# S6E1C3xD register map
Vendor: Cypress; File version: 2.1
CPU: CM0PLUS r0p1, little endian, no MPU, no FPU, 2 interrupt priority bits
Registers are 32-bit, read-write, reset 0x0 unless marked. A register's access mark holds for its fields unless they carry their own. Offsets are from the block's base; [hi:lo] are bit positions; {n}, {i} and the like mark numbered series.

## FASTIO — Fast GPIO Registers
Base 0xF8000000
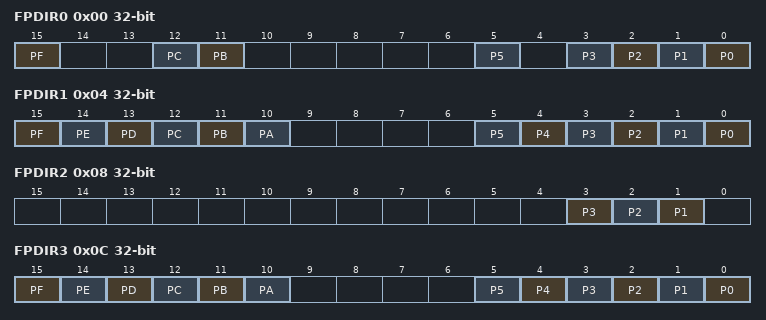
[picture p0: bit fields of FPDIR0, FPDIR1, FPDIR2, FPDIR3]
0x00 FPDIR0 ro — Fast GPIO Input Data Register 0 [BHW]
  [15] PF rw — Bit15 of FPDIR0
  [12] PC rw — Bit12 of FPDIR0
  [11] PB rw — Bit11 of FPDIR0
  [5] P5 rw — Bit5 of FPDIR0
  [n] P{n} rw (n=0..3) — Bit{n} of FPDIR0
0x04 FPDIR1 ro — Fast GPIO Input Data Register 1 [BHW]
  [15] PF rw — Bit15 of FPDIR1
  [14] PE rw — Bit14 of FPDIR1
  [13] PD rw — Bit13 of FPDIR1
  [12] PC rw — Bit12 of FPDIR1
  [11] PB rw — Bit11 of FPDIR1
  [10] PA rw — Bit10 of FPDIR1
  [n] P{n} rw (n=0..5) — Bit{n} of FPDIR1
0x08 FPDIR2 ro — Fast GPIO Input Data Register 2 [BHW]
  [3] P3 rw — Bit3 of FPDIR2
  [2] P2 rw — Bit2 of FPDIR2
  [1] P1 rw — Bit1 of FPDIR2
0x0C FPDIR3 ro — Fast GPIO Input Data Register 3 [BHW]
  [15] PF rw — Bit15 of FPDIR3
  [14] PE rw — Bit14 of FPDIR3
  [13] PD rw — Bit13 of FPDIR3
  [12] PC rw — Bit12 of FPDIR3
  [11] PB rw — Bit11 of FPDIR3
  [10] PA rw — Bit10 of FPDIR3
  [n] P{n} rw (n=0..5) — Bit{n} of FPDIR3
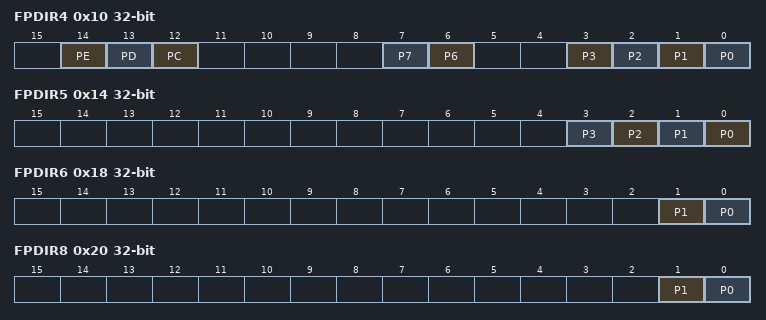
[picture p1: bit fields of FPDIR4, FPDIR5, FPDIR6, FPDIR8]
0x10 FPDIR4 ro — Fast GPIO Input Data Register 4 [BHW]
  [14] PE rw — Bit14 of FPDIR4
  [13] PD rw — Bit13 of FPDIR4
  [12] PC rw — Bit12 of FPDIR4
  [7] P7 rw — Bit7 of FPDIR4
  [6] P6 rw — Bit6 of FPDIR4
  [n] P{n} rw (n=0..3) — Bit{n} of FPDIR4
0x14 FPDIR5 ro — Fast GPIO Input Data Register 5 [BHW]
  [n] P{n} rw (n=0..3) — Bit{n} of FPDIR5
0x18 FPDIR6 ro — Fast GPIO Input Data Register 6 [BHW]
  [1] P1 rw — Bit1 of FPDIR6
  [0] P0 rw — Bit0 of FPDIR6
0x1C FPDIR7 ro reset not defined — Fast GPIO Input Data Register 7 [BHW]
0x20 FPDIR8 ro — Fast GPIO Input Data Register 8 [BHW]
  [1] P1 rw — Bit1 of FPDIR8
  [0] P0 rw — Bit0 of FPDIR8
0x24 FPDIR9 ro reset not defined — Fast GPIO Input Data Register 9 [BHW]
0x28 FPDIRA ro reset not defined — Fast GPIO Input Data Register A [BHW]
0x2C FPDIRB ro reset not defined — Fast GPIO Input Data Register B [BHW]
0x30 FPDIRC ro reset not defined — Fast GPIO Input Data Register C [BHW]
0x34 FPDIRD ro reset not defined — Fast GPIO Input Data Register D [BHW]
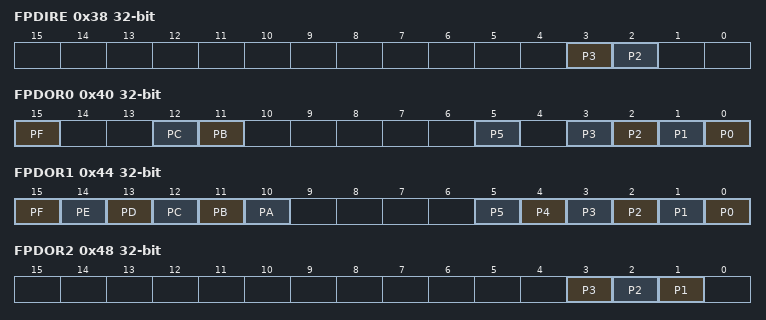
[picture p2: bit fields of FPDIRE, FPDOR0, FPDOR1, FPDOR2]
0x38 FPDIRE ro — Fast GPIO Input Data Register E [BHW]
  [3] P3 rw — Bit3 of FPDIRE
  [2] P2 rw — Bit2 of FPDIRE
0x3C FPDIRF ro reset not defined — Fast GPIO Input Data Register F [BHW]
0x40 FPDOR0 — Fast GPIO Output Data Register 0 [BHW]
  [15] PF — Bit15 of FPDOR0
  [12] PC — Bit12 of FPDOR0
  [11] PB — Bit11 of FPDOR0
  [5] P5 — Bit5 of FPDOR0
  [n] P{n} (n=0..3) — Bit{n} of FPDOR0
0x44 FPDOR1 — Fast GPIO Output Data Register 1 [BHW]
  [15] PF — Bit15 of FPDOR1
  [14] PE — Bit14 of FPDOR1
  [13] PD — Bit13 of FPDOR1
  [12] PC — Bit12 of FPDOR1
  [11] PB — Bit11 of FPDOR1
  [10] PA — Bit10 of FPDOR1
  [n] P{n} (n=0..5) — Bit{n} of FPDOR1
0x48 FPDOR2 — Fast GPIO Output Data Register 2 [BHW]
  [3] P3 — Bit3 of FPDOR2
  [2] P2 — Bit2 of FPDOR2
  [1] P1 — Bit1 of FPDOR2
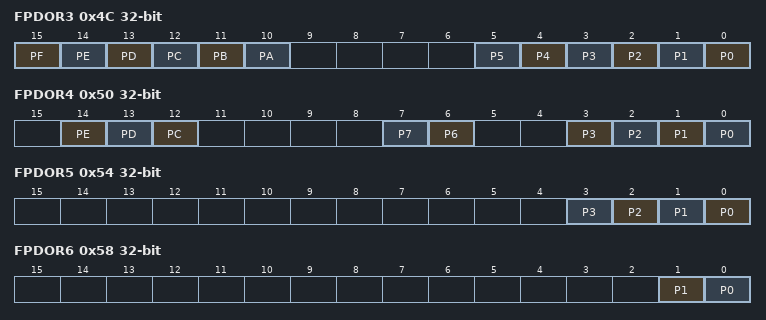
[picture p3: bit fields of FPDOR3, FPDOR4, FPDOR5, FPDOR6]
0x4C FPDOR3 — Fast GPIO Output Data Register 3 [BHW]
  [15] PF — Bit15 of FPDOR3
  [14] PE — Bit14 of FPDOR3
  [13] PD — Bit13 of FPDOR3
  [12] PC — Bit12 of FPDOR3
  [11] PB — Bit11 of FPDOR3
  [10] PA — Bit10 of FPDOR3
  [n] P{n} (n=0..5) — Bit{n} of FPDOR3
0x50 FPDOR4 — Fast GPIO Output Data Register 4 [BHW]
  [14] PE — Bit14 of FPDOR4
  [13] PD — Bit13 of FPDOR4
  [12] PC — Bit12 of FPDOR4
  [7] P7 — Bit7 of FPDOR4
  [6] P6 — Bit6 of FPDOR4
  [n] P{n} (n=0..3) — Bit{n} of FPDOR4
0x54 FPDOR5 — Fast GPIO Output Data Register 5 [BHW]
  [n] P{n} (n=0..3) — Bit{n} of FPDOR5
0x58 FPDOR6 — Fast GPIO Output Data Register 6 [BHW]
  [1] P1 — Bit1 of FPDOR6
  [0] P0 — Bit0 of FPDOR6
0x5C FPDOR7 reset not defined — Fast GPIO Output Data Register 7 [BHW]
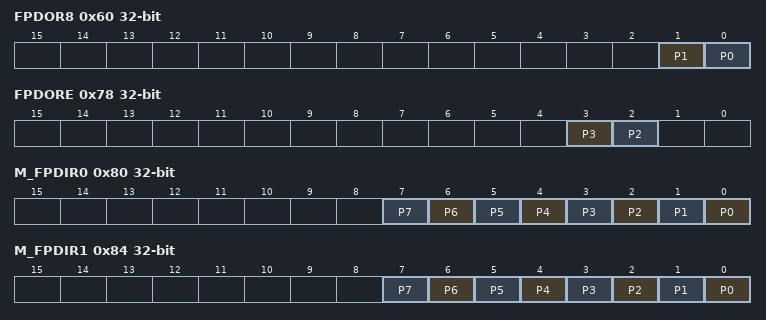
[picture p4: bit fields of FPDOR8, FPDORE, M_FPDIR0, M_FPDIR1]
0x60 FPDOR8 — Fast GPIO Output Data Register 8 [BHW]
  [1] P1 — Bit1 of FPDOR8
  [0] P0 — Bit0 of FPDOR8
0x64 FPDOR9 reset not defined — Fast GPIO Output Data Register 9 [BHW]
0x68 FPDORA reset not defined — Fast GPIO Output Data Register A [BHW]
0x6C FPDORB reset not defined — Fast GPIO Output Data Register B [BHW]
0x70 FPDORC reset not defined — Fast GPIO Output Data Register C [BHW]
0x74 FPDORD reset not defined — Fast GPIO Output Data Register D [BHW]
0x78 FPDORE — Fast GPIO Output Data Register E [BHW]
  [3] P3 — Bit3 of FPDORE
  [2] P2 — Bit2 of FPDORE
0x7C FPDORF reset not defined — Fast GPIO Output Data Register F [BHW]
0x80 M_FPDIR0 ro — Mirror Fast GPIO Input Data Register 0 [BHW]
  [n] P{n} rw (n=0..7) — Bit{n} of M_FPDIR0
0x84 M_FPDIR1 ro — Mirror Fast GPIO Input Data Register 1 [BHW]
  [n] P{n} rw (n=0..7) — Bit{n} of M_FPDIR1
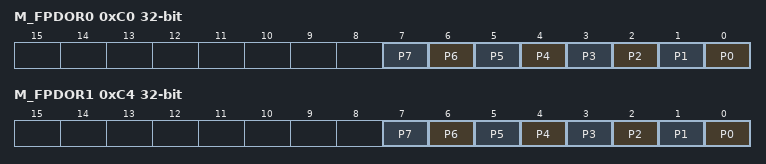
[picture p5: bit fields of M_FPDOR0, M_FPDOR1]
0xC0 M_FPDOR0 — Mirror Fast GPIO Output Data Register 0 [BHW]
  [n] P{n} (n=0..7) — Bit{n} of M_FPDOR0
0xC4 M_FPDOR1 — Mirror Fast GPIO Output Data Register 1 [BHW]
  [n] P{n} (n=0..7) — Bit{n} of M_FPDOR1
